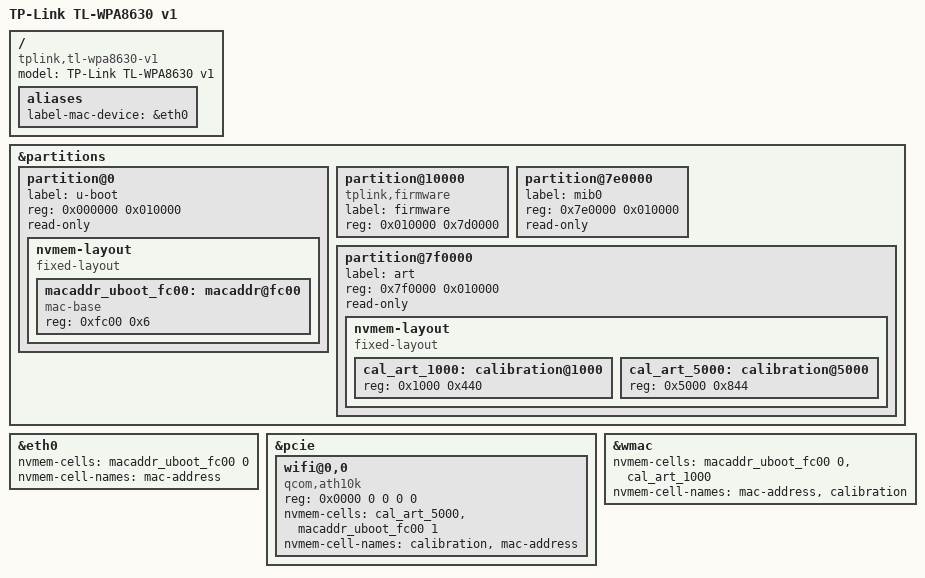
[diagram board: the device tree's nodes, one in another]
// SPDX-License-Identifier: GPL-2.0-or-later OR MIT

#include "qca9563_tplink_tl-wpa8630.dtsi"

/ {
	compatible = "tplink,tl-wpa8630-v1", "qca,qca9563";
	model = "TP-Link TL-WPA8630 v1";

	aliases {
		label-mac-device = &eth0;
	};
};

&partitions {
	partition@0 {
		label = "u-boot";
		reg = <0x000000 0x010000>;
		read-only;

		nvmem-layout {
			compatible = "fixed-layout";
			#address-cells = <1>;
			#size-cells = <1>;

			macaddr_uboot_fc00: macaddr@fc00 {
				compatible = "mac-base";
				reg = <0xfc00 0x6>;
				#nvmem-cell-cells = <1>;
			};
		};
	};

	partition@10000 {
		compatible = "tplink,firmware";
		label = "firmware";
		reg = <0x010000 0x7d0000>;
	};

	partition@7e0000 {
		label = "mib0";
		reg = <0x7e0000 0x010000>;
		read-only;
	};

	partition@7f0000 {
		label = "art";
		reg = <0x7f0000 0x010000>;
		read-only;

		nvmem-layout {
			compatible = "fixed-layout";
			#address-cells = <1>;
			#size-cells = <1>;

			cal_art_1000: calibration@1000 {
				reg = <0x1000 0x440>;
			};

			cal_art_5000: calibration@5000 {
				reg = <0x5000 0x844>;
			};
		};
	};
};

&eth0 {
	nvmem-cells = <&macaddr_uboot_fc00 0>;
	nvmem-cell-names = "mac-address";
};

&pcie {
	wifi@0,0 {
		compatible = "qcom,ath10k";
		reg = <0x0000 0 0 0 0>;
		nvmem-cells = <&cal_art_5000>, <&macaddr_uboot_fc00 1>;
		nvmem-cell-names = "calibration", "mac-address";
	};
};

&wmac {
	nvmem-cells = <&macaddr_uboot_fc00 0>, <&cal_art_1000>;
	nvmem-cell-names = "mac-address", "calibration";
};
